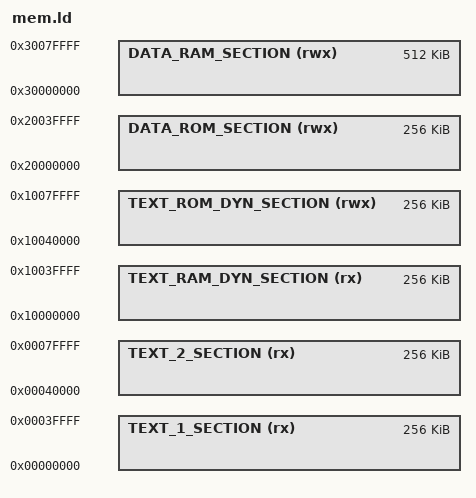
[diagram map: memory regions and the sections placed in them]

__STACK_SIZE = 4K;


/* Linker script to configure memory regions. */
MEMORY
{
   TEXT_1_SECTION (rx) : ORIGIN = 0x00000000, LENGTH = 256k
   TEXT_2_SECTION (rx) : ORIGIN = 0x00040000, LENGTH = 256k
   TEXT_RAM_DYN_SECTION (rx) : ORIGIN = 0x10000000, LENGTH = 256k 

   TEXT_ROM_DYN_SECTION (rwx) : ORIGIN = 0x10040000, LENGTH = 256k
   
   DATA_ROM_SECTION (rwx) : ORIGIN = 0x20000000, LENGTH = 256k
   DATA_RAM_SECTION (rwx) : ORIGIN = 0x30000000, LENGTH = 512k
}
